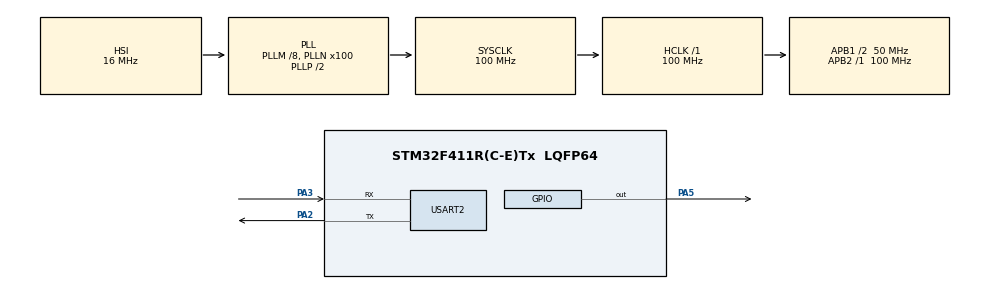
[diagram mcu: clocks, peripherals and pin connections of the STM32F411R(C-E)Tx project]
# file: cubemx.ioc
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Mcu.Family=STM32F4
Mcu.Name=STM32F411R(C-E)Tx
Mcu.Package=LQFP64
NVIC.PriorityGroup=NVIC_PRIORITYGROUP_4
PA2.Mode=Asynchronous
PA2.Signal=USART2_TX
PA3.Mode=Asynchronous
PA3.Signal=USART2_RX
PA5.Signal=GPIO_Output
ProjectManager.HeapSize=0x400
ProjectManager.StackSize=0x200
ProjectManager.TargetToolchain=TrueSTUDIO
RCC.48MHZClocksFreq_Value=50000000
RCC.AHBFreq_Value=100000000
RCC.APB1CLKDivider=RCC_HCLK_DIV2
RCC.APB1Freq_Value=50000000
RCC.APB1TimCLKDivider=1
RCC.APB1TimFreq_Value=50000000
RCC.APB2Freq_Value=100000000
RCC.APB2TimFreq_Value=100000000
RCC.CortexFreq_Value=100000000
RCC.HCLKFreq_Value=100000000
RCC.HSE_VALUE=25000000
RCC.HSI_VALUE=16000000
RCC.LSE_VALUE=32768
RCC.PLLM=8
RCC.PLLN=100
RCC.SYSCLKFreq_VALUE=100000000
RCC.SYSCLKSource=RCC_SYSCLKSOURCE_PLLCLK
RCC.VCOOutputFreq_Value=200000000
VP_WWDG_VS_WWDG.Mode=WWDG_Activate
WWDG.Counter=127
WWDG.Prescaler=WWDG_PRESCALER_8
WWDG.Window=126
board=cubemx

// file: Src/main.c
/**
  ******************************************************************************
  * File Name          : main.c
  * Description        : Main program body
  ******************************************************************************
  *
  * COPYRIGHT(c) 2016 STMicroelectronics
  *
  * Redistribution and use in source and binary forms, with or without modification,
  * are permitted provided that the following conditions are met:
  *   1. Redistributions of source code must retain the above copyright notice,
  *      this list of conditions and the following disclaimer.
  *   2. Redistributions in binary form must reproduce the above copyright notice,
  *      this list of conditions and the following disclaimer in the documentation
  *      and/or other materials provided with the distribution.
  *   3. Neither the name of STMicroelectronics nor the names of its contributors
  *      may be used to endorse or promote products derived from this software
  *      without specific prior written permission.
  *
  * THIS SOFTWARE IS PROVIDED BY THE COPYRIGHT HOLDERS AND CONTRIBUTORS "AS IS"
  * AND ANY EXPRESS OR IMPLIED WARRANTIES, INCLUDING, BUT NOT LIMITED TO, THE
  * IMPLIED WARRANTIES OF MERCHANTABILITY AND FITNESS FOR A PARTICULAR PURPOSE ARE
  * DISCLAIMED. IN NO EVENT SHALL THE COPYRIGHT HOLDER OR CONTRIBUTORS BE LIABLE
  * FOR ANY DIRECT, INDIRECT, INCIDENTAL, SPECIAL, EXEMPLARY, OR CONSEQUENTIAL
  * DAMAGES (INCLUDING, BUT NOT LIMITED TO, PROCUREMENT OF SUBSTITUTE GOODS OR
  * SERVICES; LOSS OF USE, DATA, OR PROFITS; OR BUSINESS INTERRUPTION) HOWEVER
  * CAUSED AND ON ANY THEORY OF LIABILITY, WHETHER IN CONTRACT, STRICT LIABILITY,
  * OR TORT (INCLUDING NEGLIGENCE OR OTHERWISE) ARISING IN ANY WAY OUT OF THE USE
  * OF THIS SOFTWARE, EVEN IF ADVISED OF THE POSSIBILITY OF SUCH DAMAGE.
  *
  ******************************************************************************
  */
#include "stm32f4xx_hal.h"

UART_HandleTypeDef huart2;

WWDG_HandleTypeDef hwwdg;

/* USER CODE BEGIN PV */
/* Private variables ---------------------------------------------------------*/

/* USER CODE END PV */

void SystemClock_Config(void);
static void MX_GPIO_Init(void);
static void MX_WWDG_Init(void);
static void MX_USART2_UART_Init(void);

/* USER CODE BEGIN PFP */
/* Private function prototypes -----------------------------------------------*/
void wwdg_main();
/* USER CODE END PFP */

int main(void)
{

  /* MCU Configuration----------------------------------------------------------*/

  /* Reset of all peripherals, Initializes the Flash interface and the Systick. */
  HAL_Init();

  /* Configure the system clock */
  SystemClock_Config();

  /* Initialize all configured peripherals */
  MX_GPIO_Init();
  MX_WWDG_Init();
  MX_USART2_UART_Init();

  /* USER CODE BEGIN 2 */
  wwdg_main();
  /* USER CODE END 2 */

  /* Infinite loop */
  while (1)
  {

  }

}

/** System Clock Configuration
*/
void SystemClock_Config(void)
{

  RCC_OscInitTypeDef RCC_OscInitStruct;
  RCC_ClkInitTypeDef RCC_ClkInitStruct;

  __PWR_CLK_ENABLE();

  __HAL_PWR_VOLTAGESCALING_CONFIG(PWR_REGULATOR_VOLTAGE_SCALE1);

  RCC_OscInitStruct.OscillatorType = RCC_OSCILLATORTYPE_HSI;
  RCC_OscInitStruct.HSIState = RCC_HSI_ON;
  RCC_OscInitStruct.HSICalibrationValue = 16;
  RCC_OscInitStruct.PLL.PLLState = RCC_PLL_ON;
  RCC_OscInitStruct.PLL.PLLSource = RCC_PLLSOURCE_HSI;
  RCC_OscInitStruct.PLL.PLLM = 8;
  RCC_OscInitStruct.PLL.PLLN = 100;
  RCC_OscInitStruct.PLL.PLLP = RCC_PLLP_DIV2;
  RCC_OscInitStruct.PLL.PLLQ = 4;
  HAL_RCC_OscConfig(&RCC_OscInitStruct);

  RCC_ClkInitStruct.ClockType = RCC_CLOCKTYPE_HCLK|RCC_CLOCKTYPE_SYSCLK
                              |RCC_CLOCKTYPE_PCLK1|RCC_CLOCKTYPE_PCLK2;
  RCC_ClkInitStruct.SYSCLKSource = RCC_SYSCLKSOURCE_PLLCLK;
  RCC_ClkInitStruct.AHBCLKDivider = RCC_SYSCLK_DIV1;
  RCC_ClkInitStruct.APB1CLKDivider = RCC_HCLK_DIV2;
  RCC_ClkInitStruct.APB2CLKDivider = RCC_HCLK_DIV1;
  HAL_RCC_ClockConfig(&RCC_ClkInitStruct, FLASH_LATENCY_3);

  HAL_SYSTICK_Config(HAL_RCC_GetHCLKFreq()/1000);

  HAL_SYSTICK_CLKSourceConfig(SYSTICK_CLKSOURCE_HCLK);

  /* SysTick_IRQn interrupt configuration */
  HAL_NVIC_SetPriority(SysTick_IRQn, 0, 0);
}

/* USART2 init function */
void MX_USART2_UART_Init(void)
{

  huart2.Instance = USART2;
  huart2.Init.BaudRate = 115200;
  huart2.Init.WordLength = UART_WORDLENGTH_8B;
  huart2.Init.StopBits = UART_STOPBITS_1;
  huart2.Init.Parity = UART_PARITY_NONE;
  huart2.Init.Mode = UART_MODE_TX_RX;
  huart2.Init.HwFlowCtl = UART_HWCONTROL_NONE;
  huart2.Init.OverSampling = UART_OVERSAMPLING_16;
  HAL_UART_Init(&huart2);

}

/* WWDG init function */
void MX_WWDG_Init(void)
{

  hwwdg.Instance = WWDG;
  hwwdg.Init.Prescaler = WWDG_PRESCALER_8;
  hwwdg.Init.Window = 126;
  hwwdg.Init.Counter = 127;
  HAL_WWDG_Init(&hwwdg);

}

/** Configure pins as
        * Analog
        * Input
        * Output
        * EVENT_OUT
        * EXTI
*/
void MX_GPIO_Init(void)
{

  GPIO_InitTypeDef GPIO_InitStruct;

  /* GPIO Ports Clock Enable */
  __GPIOA_CLK_ENABLE();

  /*Configure GPIO pin Output Level */
  HAL_GPIO_WritePin(GPIOA, GPIO_PIN_5, GPIO_PIN_RESET);

  /*Configure GPIO pin : PA5 */
  GPIO_InitStruct.Pin = GPIO_PIN_5;
  GPIO_InitStruct.Mode = GPIO_MODE_OUTPUT_PP;
  GPIO_InitStruct.Pull = GPIO_NOPULL;
  GPIO_InitStruct.Speed = GPIO_SPEED_LOW;
  HAL_GPIO_Init(GPIOA, &GPIO_InitStruct);

}

/************************ (C) COPYRIGHT STMicroelectronics *****END OF FILE****/
